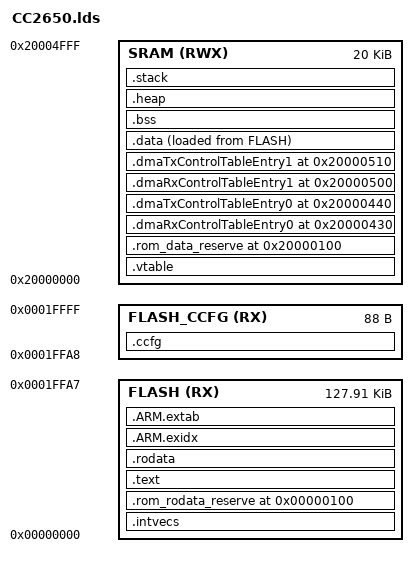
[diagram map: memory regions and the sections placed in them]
/*
 * Copyright (c) 2016, Texas Instruments Incorporated
 * All rights reserved.
 *
 * Redistribution and use in source and binary forms, with or without
 * modification, are permitted provided that the following conditions
 * are met:
 *
 * *  Redistributions of source code must retain the above copyright
 *    notice, this list of conditions and the following disclaimer.
 *
 * *  Redistributions in binary form must reproduce the above copyright
 *    notice, this list of conditions and the following disclaimer in the
 *    documentation and/or other materials provided with the distribution.
 *
 * *  Neither the name of Texas Instruments Incorporated nor the names of
 *    its contributors may be used to endorse or promote products derived
 *    from this software without specific prior written permission.
 *
 * THIS SOFTWARE IS PROVIDED BY THE COPYRIGHT HOLDERS AND CONTRIBUTORS "AS IS"
 * AND ANY EXPRESS OR IMPLIED WARRANTIES, INCLUDING, BUT NOT LIMITED TO,
 * THE IMPLIED WARRANTIES OF MERCHANTABILITY AND FITNESS FOR A PARTICULAR
 * PURPOSE ARE DISCLAIMED. IN NO EVENT SHALL THE COPYRIGHT OWNER OR
 * CONTRIBUTORS BE LIABLE FOR ANY DIRECT, INDIRECT, INCIDENTAL, SPECIAL,
 * EXEMPLARY, OR CONSEQUENTIAL DAMAGES (INCLUDING, BUT NOT LIMITED TO,
 * PROCUREMENT OF SUBSTITUTE GOODS OR SERVICES; LOSS OF USE, DATA, OR PROFITS;
 * OR BUSINESS INTERRUPTION) HOWEVER CAUSED AND ON ANY THEORY OF LIABILITY,
 * WHETHER IN CONTRACT, STRICT LIABILITY, OR TORT (INCLUDING NEGLIGENCE OR
 * OTHERWISE) ARISING IN ANY WAY OUT OF THE USE OF THIS SOFTWARE,
 * EVEN IF ADVISED OF THE POSSIBILITY OF SUCH DAMAGE.
 */

MEMORY
{
    FLASH (RX)      : ORIGIN = 0x00000000, LENGTH = 0x0001ffa8
    /*
     * Customer Configuration Area and Bootloader Backdoor configuration in
     * flash, 40 bytes
     */
    FLASH_CCFG (RX) : ORIGIN = 0x0001ffa8, LENGTH = 0x00000058
    SRAM (RWX)      : ORIGIN = 0x20000000, LENGTH = 0x00005000
}

REGION_ALIAS("REGION_TEXT", FLASH);
REGION_ALIAS("REGION_BSS", SRAM);
REGION_ALIAS("REGION_DATA", SRAM);
REGION_ALIAS("REGION_STACK", SRAM);
REGION_ALIAS("REGION_HEAP", SRAM);
REGION_ALIAS("REGION_ARM_EXIDX", FLASH);
REGION_ALIAS("REGION_ARM_EXTAB", FLASH);

SECTIONS {

    PROVIDE (_intvecs_base_address =
        DEFINED(_intvecs_base_address) ? _intvecs_base_address : 0x0);

    .intvecs (_intvecs_base_address) : AT (_intvecs_base_address) {
        KEEP (*(.intvecs))
    } > REGION_TEXT

    PROVIDE (_vtable_base_address =
        DEFINED(_vtable_base_address) ? _vtable_base_address : 0x20000000);

    .vtable (_vtable_base_address) (NOLOAD) : {
        KEEP (*(.vtable))
    } > REGION_DATA

    /* if a ROM-only symbol is present, then ROM is being used.
     * Reserve memory for surgically placed module states.
     */
    _rom_data_start = 0x20000100;
    _rom_data_size = DEFINED(ti_sysbios_rom_ROM_ti_sysbios_family_arm_cc26xx_Timer_getCount64__E) ? 0x104 : 0;

    .rom_data_reserve (_rom_data_start): {
        . += _rom_data_size;
    } > REGION_DATA

    /* these hard-coded addrs are needed by the TI-RTOS SPICC26XXDMA driver
     * and must match appropriate offsets from UDMACC26XX_CONFIG_BASE defined
     * by ti/drivers/dma/UDMACC26XX.h
     */
    UDMACC26XX_dmaRxControlTableEntry0_is_placed = 0;
    .dmaRxControlTableEntry0 0x20000430 : AT (0x20000430) {*(.dmaRxControlTableEntry0)} > REGION_DATA

    UDMACC26XX_dmaTxControlTableEntry0_is_placed = 0;
    .dmaTxControlTableEntry0 0x20000440 : AT (0x20000440) {*(.dmaTxControlTableEntry0)} > REGION_DATA

    UDMACC26XX_dmaRxControlTableEntry1_is_placed = 0;
    .dmaRxControlTableEntry1 0x20000500 : AT (0x20000500) {*(.dmaRxControlTableEntry1)} > REGION_DATA

    UDMACC26XX_dmaTxControlTableEntry1_is_placed = 0;
    .dmaTxControlTableEntry1 0x20000510 : AT (0x20000510) {*(.dmaTxControlTableEntry1)} > REGION_DATA

    /* if a ROM-only symbol is present, then ROM is being used.
     * Reserve memory for surgically placed config constants.
     */
    _rom_rodata_start = 0x100;
    _rom_rodata_size = DEFINED(ti_sysbios_rom_ROM_ti_sysbios_family_arm_cc26xx_Timer_getCount64__E) ? 0x500 : 0;

    .rom_rodata_reserve (_rom_rodata_start): {
        . += _rom_rodata_size;
    } > REGION_TEXT AT> REGION_TEXT

    .text : {
        CREATE_OBJECT_SYMBOLS
        *(.text)
        *(.text.*)
        . = ALIGN(0x4);
        KEEP (*(.ctors))
        . = ALIGN(0x4);
        KEEP (*(.dtors))
        . = ALIGN(0x4);
        __init_array_start = .;
        KEEP (*(.init_array*))
        __init_array_end = .;
        *(.init)
        *(.fini*)
    } > REGION_TEXT AT> REGION_TEXT

    PROVIDE (__etext = .);
    PROVIDE (_etext = .);
    PROVIDE (etext = .);

    .rodata : {
        *(.rodata)
        *(.rodata.*)
    } > REGION_TEXT AT> REGION_TEXT

    .data : ALIGN(4) {
        __data_load__ = LOADADDR (.data);
        __data_start__ = .;
        *(.data)
        *(.data.*)
        . = ALIGN (4);
        __data_end__ = .;
    } > REGION_DATA AT> REGION_TEXT

    .ARM.exidx : {
        __exidx_start = .;
        *(.ARM.exidx* .gnu.linkonce.armexidx.*)
        __exidx_end = .;
    } > REGION_ARM_EXIDX AT> REGION_ARM_EXIDX

    .ARM.extab : {
        *(.ARM.extab* .gnu.linkonce.armextab.*)
    } > REGION_ARM_EXTAB AT> REGION_ARM_EXTAB

    .ccfg : {
        KEEP (*(.ccfg))
    } > FLASH_CCFG AT> FLASH_CCFG

    .bss : {
        __bss_start__ = .;
        *(.shbss)
        *(.bss)
        *(.bss.*)
        *(COMMON)
        . = ALIGN (4);
        __bss_end__ = .;
    } > REGION_BSS AT> REGION_BSS

    .heap : {
        __heap_start__ = .;
        end = __heap_start__;
        _end = end;
        __end = end;
        KEEP(*(.heap))
        __heap_end__ = .;
        __HeapLimit = __heap_end__;
    } > REGION_HEAP AT> REGION_HEAP

    .stack (NOLOAD) : ALIGN(0x8) {
        _stack = .;
        __stack = .;
        KEEP(*(.stack))
    } > REGION_STACK AT> REGION_STACK
}
